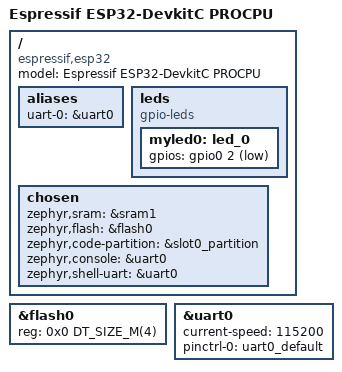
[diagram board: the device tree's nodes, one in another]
/*
 * Copyright (c) 2023-2025 Espressif Systems (Shanghai) Co., Ltd.
 *
 * SPDX-License-Identifier: Apache-2.0
 */
/dts-v1/;

#include <espressif/esp32/esp32.dtsi>
#include "esp32_devkitc-pinctrl.dtsi"
#include <zephyr/dt-bindings/input/input-event-codes.h>
#include <espressif/partitions_0x1000_amp.dtsi>

/ {
	model = "Espressif ESP32-DevkitC PROCPU";
	compatible = "espressif,esp32";


	aliases {
		uart-0 = &uart0;
	};

    leds {
        compatible = "gpio-leds";

        myled0: led_0 {
            gpios = <&gpio0 2 GPIO_ACTIVE_LOW>;
        };
    };

	chosen {
		zephyr,sram = &sram1;
		zephyr,flash = &flash0;
		zephyr,code-partition = &slot0_partition;
		zephyr,console = &uart0;
		zephyr,shell-uart = &uart0;
	};
};

&flash0 {
	reg = <0x0 DT_SIZE_M(4)>;
	ranges = <0x0 0x0 DT_SIZE_M(4)>;
};

&uart0 {
	status = "okay";
	current-speed = <115200>;
	pinctrl-0 = <&uart0_default>;
	pinctrl-names = "default";
};
